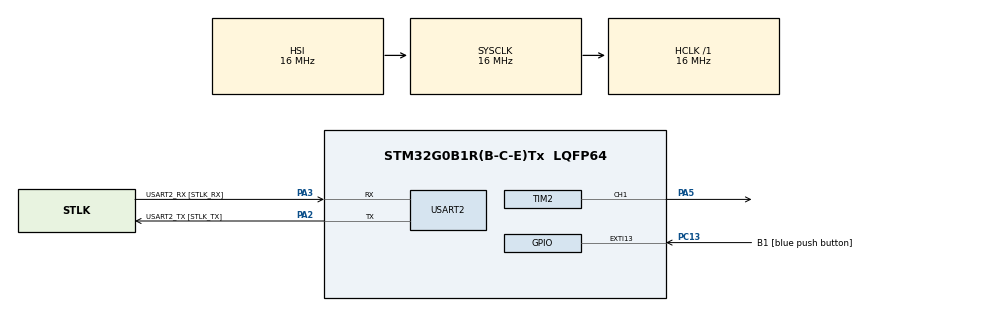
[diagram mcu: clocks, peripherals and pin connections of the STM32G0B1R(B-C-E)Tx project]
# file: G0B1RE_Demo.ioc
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Dma.DMA_GENERATOR0.0.Direction=DMA_MEMORY_TO_PERIPH
Dma.DMA_GENERATOR0.0.EventEnable=DISABLE
Dma.DMA_GENERATOR0.0.Instance=DMA1_Channel1
Dma.DMA_GENERATOR0.0.MemDataAlignment=DMA_MDATAALIGN_WORD
Dma.DMA_GENERATOR0.0.MemInc=DMA_MINC_ENABLE
Dma.DMA_GENERATOR0.0.Mode=DMA_CIRCULAR
Dma.DMA_GENERATOR0.0.PeriphDataAlignment=DMA_PDATAALIGN_WORD
Dma.DMA_GENERATOR0.0.PeriphInc=DMA_PINC_DISABLE
Dma.DMA_GENERATOR0.0.Polarity=HAL_DMAMUX_REQ_GEN_RISING
Dma.DMA_GENERATOR0.0.Priority=DMA_PRIORITY_LOW
Dma.DMA_GENERATOR0.0.RequestNumber=1
Dma.DMA_GENERATOR0.0.SignalID=HAL_DMAMUX1_REQ_GEN_EXTI13
Dma.DMA_GENERATOR0.0.SyncEnable=DISABLE
Dma.DMA_GENERATOR0.0.SyncPolarity=HAL_DMAMUX_SYNC_NO_EVENT
Dma.DMA_GENERATOR0.0.SyncRequestNumber=1
Dma.DMA_GENERATOR0.0.SyncSignalID=NONE
Dma.Request0=DMA_GENERATOR0
Mcu.Family=STM32G0
Mcu.Name=STM32G0B1R(B-C-E)Tx
Mcu.Package=LQFP64
PA13.GPIO_Label=TMS
PA13.Mode=Serial_Wire
PA13.Signal=SYS_SWDIO
PA14-BOOT0.GPIO_Label=TCK
PA14-BOOT0.Mode=Serial_Wire
PA14-BOOT0.Signal=SYS_SWCLK
PA2.GPIO_Label=USART2_TX [STLK_TX]
PA2.Mode=Asynchronous
PA2.Signal=USART2_TX
PA3.GPIO_Label=USART2_RX [STLK_RX]
PA3.Mode=Asynchronous
PA3.Signal=USART2_RX
PA5.Signal=S_TIM2_CH1_ETR
PC13.GPIO_Label=B1 [blue push button]
PC13.Signal=GPXTI13
PC14-OSC32_IN\ (PC14).Mode=LSE-External-Oscillator
PC14-OSC32_IN\ (PC14).Signal=RCC_OSC32_IN
PC15-OSC32_OUT\ (PC15).Mode=LSE-External-Oscillator
PC15-OSC32_OUT\ (PC15).Signal=RCC_OSC32_OUT
PF0-OSC_IN\ (PF0).GPIO_Label=MCO
PF0-OSC_IN\ (PF0).Mode=HSE-External-Clock-Source
PF0-OSC_IN\ (PF0).Signal=RCC_OSC_IN
ProjectManager.HeapSize=0x200
ProjectManager.StackSize=0x400
ProjectManager.TargetToolchain=STM32CubeIDE
RCC.AHBFreq_Value=16000000
RCC.CortexFreq_Value=16000000
RCC.EXTERNAL_CLOCK_VALUE=12288000
RCC.HCLKFreq_Value=16000000
RCC.HSE_VALUE=8000000
RCC.HSI48_VALUE=48000000
RCC.HSI_VALUE=16000000
RCC.SYSCLKFreq_VALUE=16000000
RCC.USBFreq_Value=48000000
RCC.VCOOutputFreq_Value=128000000
SH.S_TIM2_CH1_ETR.0=TIM2_CH1,Output Compare1 CH1
TIM2.AutoReloadPreload=TIM_AUTORELOAD_PRELOAD_ENABLE
TIM2.Channel-Output\ Compare1\ CH1=TIM_CHANNEL_1
TIM2.OCMode_1=TIM_OCMODE_TOGGLE
TIM2.Period=1000
TIM2.Prescaler=15999
TIM2.Pulse-Output\ Compare1\ CH1=500
USART2.VirtualMode-Asynchronous=VM_ASYNC
VP_SYS_VS_DBSignals.Mode=DisableDeadBatterySignals
VP_TIM2_VS_ClockSourceINT.Mode=Internal
board=NUCLEO-G0B1RE

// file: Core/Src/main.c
/* USER CODE BEGIN Header */
/**
  ******************************************************************************
  * @file           : main.c
  * @brief          : Main program body
  ******************************************************************************
  * @attention
  *
  * Copyright (c) 2025 STMicroelectronics.
  * All rights reserved.
  *
  * This software is licensed under terms that can be found in the LICENSE file
  * in the root directory of this software component.
  * If no LICENSE file comes with this software, it is provided AS-IS.
  *
  ******************************************************************************
  */
/* USER CODE END Header */
#include "main.h"

/* USER CODE BEGIN Includes */

#include "i_timer.h"
#include "i_dma.h"

/* USER CODE END Includes */

TIM_HandleTypeDef htim2;

UART_HandleTypeDef huart2;

DMA_HandleTypeDef hdma_dma_generator0;

void SystemClock_Config(void);
static void MX_GPIO_Init(void);
static void MX_DMA_Init(void);
static void MX_USART2_UART_Init(void);
static void MX_TIM2_Init(void);

int main(void)
{

  /* MCU Configuration--------------------------------------------------------*/

  /* Reset of all peripherals, Initializes the Flash interface and the Systick. */
  HAL_Init();

  /* Configure the system clock */
  SystemClock_Config();

  /* Initialize all configured peripherals */
  MX_GPIO_Init();
  MX_DMA_Init();
  MX_USART2_UART_Init();
  MX_TIM2_Init();
  /* USER CODE BEGIN 2 */

  //gpio_init();
  tim_init();
  dma_init();

  /* USER CODE END 2 */

  /* Infinite loop */
  /* USER CODE BEGIN WHILE */
  while (1)
  {

		HAL_PWR_EnterSLEEPMode(PWR_MAINREGULATOR_ON, PWR_STOPENTRY_WFI);
  	//HAL_PWR_EnterSLEEPMode(PWR_MAINREGULATOR_ON, PWR_SLEEPENTRY_WFI);

    /* USER CODE END WHILE */

  }
}

void SystemClock_Config(void)
{
  RCC_OscInitTypeDef RCC_OscInitStruct = {0};
  RCC_ClkInitTypeDef RCC_ClkInitStruct = {0};

  /** Configure the main internal regulator output voltage
  */
  HAL_PWREx_ControlVoltageScaling(PWR_REGULATOR_VOLTAGE_SCALE1);

  /** Initializes the RCC Oscillators according to the specified parameters
  * in the RCC_OscInitTypeDef structure.
  */
  RCC_OscInitStruct.OscillatorType = RCC_OSCILLATORTYPE_HSI;
  RCC_OscInitStruct.HSIState = RCC_HSI_ON;
  RCC_OscInitStruct.HSIDiv = RCC_HSI_DIV1;
  RCC_OscInitStruct.HSICalibrationValue = RCC_HSICALIBRATION_DEFAULT;
  RCC_OscInitStruct.PLL.PLLState = RCC_PLL_NONE;
  if (HAL_RCC_OscConfig(&RCC_OscInitStruct) != HAL_OK)
  {
    Error_Handler();
  }

  /** Initializes the CPU, AHB and APB buses clocks
  */
  RCC_ClkInitStruct.ClockType = RCC_CLOCKTYPE_HCLK|RCC_CLOCKTYPE_SYSCLK
                              |RCC_CLOCKTYPE_PCLK1;
  RCC_ClkInitStruct.SYSCLKSource = RCC_SYSCLKSOURCE_HSI;
  RCC_ClkInitStruct.AHBCLKDivider = RCC_SYSCLK_DIV1;
  RCC_ClkInitStruct.APB1CLKDivider = RCC_HCLK_DIV1;

  if (HAL_RCC_ClockConfig(&RCC_ClkInitStruct, FLASH_LATENCY_0) != HAL_OK)
  {
    Error_Handler();
  }
}

static void MX_TIM2_Init(void)
{

  TIM_ClockConfigTypeDef sClockSourceConfig = {0};
  TIM_MasterConfigTypeDef sMasterConfig = {0};
  TIM_OC_InitTypeDef sConfigOC = {0};

  htim2.Instance = TIM2;
  htim2.Init.Prescaler = 15999;
  htim2.Init.CounterMode = TIM_COUNTERMODE_UP;
  htim2.Init.Period = 1000;
  htim2.Init.ClockDivision = TIM_CLOCKDIVISION_DIV1;
  htim2.Init.AutoReloadPreload = TIM_AUTORELOAD_PRELOAD_ENABLE;
  if (HAL_TIM_Base_Init(&htim2) != HAL_OK)
  {
    Error_Handler();
  }
  sClockSourceConfig.ClockSource = TIM_CLOCKSOURCE_INTERNAL;
  if (HAL_TIM_ConfigClockSource(&htim2, &sClockSourceConfig) != HAL_OK)
  {
    Error_Handler();
  }
  if (HAL_TIM_OC_Init(&htim2) != HAL_OK)
  {
    Error_Handler();
  }
  sMasterConfig.MasterOutputTrigger = TIM_TRGO_RESET;
  sMasterConfig.MasterSlaveMode = TIM_MASTERSLAVEMODE_DISABLE;
  if (HAL_TIMEx_MasterConfigSynchronization(&htim2, &sMasterConfig) != HAL_OK)
  {
    Error_Handler();
  }
  sConfigOC.OCMode = TIM_OCMODE_TOGGLE;
  sConfigOC.Pulse = 500;
  sConfigOC.OCPolarity = TIM_OCPOLARITY_HIGH;
  sConfigOC.OCFastMode = TIM_OCFAST_DISABLE;
  if (HAL_TIM_OC_ConfigChannel(&htim2, &sConfigOC, TIM_CHANNEL_1) != HAL_OK)
  {
    Error_Handler();
  }
  HAL_TIM_MspPostInit(&htim2);

}

static void MX_USART2_UART_Init(void)
{

  huart2.Instance = USART2;
  huart2.Init.BaudRate = 115200;
  huart2.Init.WordLength = UART_WORDLENGTH_8B;
  huart2.Init.StopBits = UART_STOPBITS_1;
  huart2.Init.Parity = UART_PARITY_NONE;
  huart2.Init.Mode = UART_MODE_TX_RX;
  huart2.Init.HwFlowCtl = UART_HWCONTROL_NONE;
  huart2.Init.OverSampling = UART_OVERSAMPLING_16;
  huart2.Init.OneBitSampling = UART_ONE_BIT_SAMPLE_DISABLE;
  huart2.Init.ClockPrescaler = UART_PRESCALER_DIV1;
  huart2.AdvancedInit.AdvFeatureInit = UART_ADVFEATURE_NO_INIT;
  if (HAL_UART_Init(&huart2) != HAL_OK)
  {
    Error_Handler();
  }
  if (HAL_UARTEx_SetTxFifoThreshold(&huart2, UART_TXFIFO_THRESHOLD_1_8) != HAL_OK)
  {
    Error_Handler();
  }
  if (HAL_UARTEx_SetRxFifoThreshold(&huart2, UART_RXFIFO_THRESHOLD_1_8) != HAL_OK)
  {
    Error_Handler();
  }
  if (HAL_UARTEx_DisableFifoMode(&huart2) != HAL_OK)
  {
    Error_Handler();
  }

}

static void MX_DMA_Init(void)
{

  /* Local variables */
  HAL_DMA_MuxRequestGeneratorConfigTypeDef pRequestGeneratorConfig = {0};

  /* DMA controller clock enable */
  __HAL_RCC_DMA1_CLK_ENABLE();

  /* Configure DMA request hdma_dma_generator0 on DMA1_Channel1 */
  hdma_dma_generator0.Instance = DMA1_Channel1;
  hdma_dma_generator0.Init.Request = DMA_REQUEST_GENERATOR0;
  hdma_dma_generator0.Init.Direction = DMA_MEMORY_TO_PERIPH;
  hdma_dma_generator0.Init.PeriphInc = DMA_PINC_DISABLE;
  hdma_dma_generator0.Init.MemInc = DMA_MINC_ENABLE;
  hdma_dma_generator0.Init.PeriphDataAlignment = DMA_PDATAALIGN_WORD;
  hdma_dma_generator0.Init.MemDataAlignment = DMA_MDATAALIGN_WORD;
  hdma_dma_generator0.Init.Mode = DMA_CIRCULAR;
  hdma_dma_generator0.Init.Priority = DMA_PRIORITY_LOW;
  if (HAL_DMA_Init(&hdma_dma_generator0) != HAL_OK)
  {
    Error_Handler( );
  }

  /* Configure the DMAMUX request generator for the selected DMA channel */
  pRequestGeneratorConfig.SignalID = HAL_DMAMUX1_REQ_GEN_EXTI13;
  pRequestGeneratorConfig.Polarity = HAL_DMAMUX_REQ_GEN_RISING;
  pRequestGeneratorConfig.RequestNumber = 1;
  if (HAL_DMAEx_ConfigMuxRequestGenerator(&hdma_dma_generator0, &pRequestGeneratorConfig) != HAL_OK)
  {
    Error_Handler( );
  }

}

static void MX_GPIO_Init(void)
{
  GPIO_InitTypeDef GPIO_InitStruct = {0};

  /* GPIO Ports Clock Enable */
  __HAL_RCC_GPIOC_CLK_ENABLE();
  __HAL_RCC_GPIOF_CLK_ENABLE();
  __HAL_RCC_GPIOA_CLK_ENABLE();

  /*Configure GPIO pin : B1_Pin */
  GPIO_InitStruct.Pin = B1_Pin;
  GPIO_InitStruct.Mode = GPIO_MODE_IT_RISING;
  GPIO_InitStruct.Pull = GPIO_NOPULL;
  HAL_GPIO_Init(B1_GPIO_Port, &GPIO_InitStruct);

}

void Error_Handler(void)
{
  __disable_irq();
  while (1)
  {
  }
}
